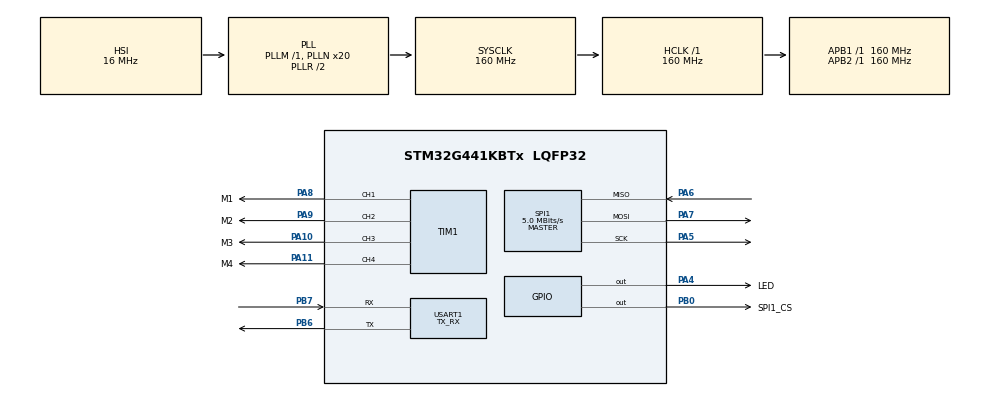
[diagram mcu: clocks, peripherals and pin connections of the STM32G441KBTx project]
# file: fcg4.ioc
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Mcu.Family=STM32G4
Mcu.Name=STM32G441KBTx
Mcu.Package=LQFP32
NVIC.PriorityGroup=NVIC_PRIORITYGROUP_4
NVIC.USART1_IRQn=true\:1\:0\:true\:false\:true\:true\:true
PA10.GPIO_Label=M3
PA10.GPIO_Speed=GPIO_SPEED_FREQ_VERY_HIGH
PA10.Signal=S_TIM1_CH3
PA11.GPIO_Label=M4
PA11.GPIO_Speed=GPIO_SPEED_FREQ_VERY_HIGH
PA11.Signal=S_TIM1_CH4
PA13.Mode=Serial_Wire
PA13.Signal=SYS_JTMS-SWDIO
PA14.Mode=Serial_Wire
PA14.Signal=SYS_JTCK-SWCLK
PA4.GPIO_Label=LED
PA4.GPIO_Speed=GPIO_SPEED_FREQ_VERY_HIGH
PA4.Signal=GPIO_Output
PA5.Mode=Full_Duplex_Master
PA5.Signal=SPI1_SCK
PA6.Mode=Full_Duplex_Master
PA6.Signal=SPI1_MISO
PA7.Mode=Full_Duplex_Master
PA7.Signal=SPI1_MOSI
PA8.GPIO_Label=M1
PA8.GPIO_Speed=GPIO_SPEED_FREQ_VERY_HIGH
PA8.Signal=S_TIM1_CH1
PA9.GPIO_Label=M2
PA9.GPIO_Speed=GPIO_SPEED_FREQ_VERY_HIGH
PA9.Signal=S_TIM1_CH2
PB0.GPIO_Label=SPI1_CS
PB0.GPIO_Speed=GPIO_SPEED_FREQ_VERY_HIGH
PB0.PinState=GPIO_PIN_SET
PB0.Signal=GPIO_Output
PB6.GPIO_Speed=GPIO_SPEED_FREQ_VERY_HIGH
PB6.Mode=Asynchronous
PB6.Signal=USART1_TX
PB7.GPIO_Speed=GPIO_SPEED_FREQ_VERY_HIGH
PB7.Mode=Asynchronous
PB7.Signal=USART1_RX
ProjectManager.HeapSize=0x200
ProjectManager.StackSize=0x400
ProjectManager.TargetToolchain=STM32CubeIDE
RCC.ADC12Freq_Value=160000000
RCC.AHBFreq_Value=160000000
RCC.APB1Freq_Value=160000000
RCC.APB1TimFreq_Value=160000000
RCC.APB2Freq_Value=160000000
RCC.APB2TimFreq_Value=160000000
RCC.CortexFreq_Value=160000000
RCC.EXTERNAL_CLOCK_VALUE=12288000
RCC.HCLKFreq_Value=160000000
RCC.HSE_VALUE=8000000
RCC.HSI48_VALUE=48000000
RCC.HSI_VALUE=16000000
RCC.LSE_VALUE=32768
RCC.PLLN=20
RCC.SYSCLKFreq_VALUE=160000000
RCC.SYSCLKSource=RCC_SYSCLKSOURCE_PLLCLK
RCC.USBFreq_Value=160000000
RCC.VCOOutputFreq_Value=320000000
SH.S_TIM1_CH1.0=TIM1_CH1,PWM Generation1 CH1
SH.S_TIM1_CH2.0=TIM1_CH2,PWM Generation2 CH2
SH.S_TIM1_CH3.0=TIM1_CH3,PWM Generation3 CH3
SH.S_TIM1_CH4.0=TIM1_CH4,PWM Generation4 CH4
SPI1.BaudRatePrescaler=SPI_BAUDRATEPRESCALER_32
SPI1.CLKPhase=SPI_PHASE_2EDGE
SPI1.CLKPolarity=SPI_POLARITY_HIGH
SPI1.CalculateBaudRate=5.0 MBits/s
SPI1.DataSize=SPI_DATASIZE_8BIT
SPI1.Direction=SPI_DIRECTION_2LINES
SPI1.Mode=SPI_MODE_MASTER
SPI1.VirtualType=VM_MASTER
TIM1.Channel-PWM\ Generation1\ CH1=TIM_CHANNEL_1
TIM1.Channel-PWM\ Generation2\ CH2=TIM_CHANNEL_2
TIM1.Channel-PWM\ Generation3\ CH3=TIM_CHANNEL_3
TIM1.Channel-PWM\ Generation4\ CH4=TIM_CHANNEL_4
TIM2.Prescaler=160-1
USART1.AutoBaudRateEnableParam=UART_ADVFEATURE_AUTOBAUDRATE_ENABLE
USART1.Mode=MODE_TX_RX
USART1.OneBitSampling=UART_ONE_BIT_SAMPLE_DISABLE
USART1.VirtualMode-Asynchronous=VM_ASYNC
VP_SYS_VS_DBSignals.Mode=DisableDeadBatterySignals
VP_TIM1_VS_ClockSourceINT.Mode=Internal
VP_TIM2_VS_ClockSourceINT.Mode=Internal
board=custom

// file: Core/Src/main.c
/* USER CODE BEGIN Header */
/**
 ******************************************************************************
 * @file           : main.c
 * @brief          : Main program body
 ******************************************************************************
 * @attention
 *
 * <h2><center>&copy; Copyright (c) 2021 STMicroelectronics.
 * All rights reserved.</center></h2>
 *
 * This software component is licensed by ST under BSD 3-Clause license,
 * the "License"; You may not use this file except in compliance with the
 * License. You may obtain a copy of the License at:
 *                        opensource.org/licenses/BSD-3-Clause
 *
 ******************************************************************************
 */
/* USER CODE END Header */
#include "main.h"
#include "spi.h"
#include "tim.h"
#include "usart.h"
#include "gpio.h"

/* USER CODE BEGIN Includes */
#include "flight_controler.h"
/* USER CODE END Includes */

void SystemClock_Config(void);

int main(void)
{

  /* MCU Configuration--------------------------------------------------------*/

  /* Reset of all peripherals, Initializes the Flash interface and the Systick. */
  HAL_Init();

  /* Configure the system clock */
  SystemClock_Config();

  /* Initialize all configured peripherals */
  MX_GPIO_Init();
  MX_SPI1_Init();
  MX_TIM1_Init();
  MX_USART1_UART_Init();
  MX_TIM2_Init();
  /* USER CODE BEGIN 2 */

	flight_controler_init();
  /* USER CODE END 2 */

  /* Infinite loop */
  /* USER CODE BEGIN WHILE */
	while (1) {
		flight_controler_run();

    /* USER CODE END WHILE */

	}
}

void SystemClock_Config(void)
{
  RCC_OscInitTypeDef RCC_OscInitStruct = {0};
  RCC_ClkInitTypeDef RCC_ClkInitStruct = {0};
  RCC_PeriphCLKInitTypeDef PeriphClkInit = {0};

  /** Configure the main internal regulator output voltage
  */
  HAL_PWREx_ControlVoltageScaling(PWR_REGULATOR_VOLTAGE_SCALE1_BOOST);
  /** Initializes the RCC Oscillators according to the specified parameters
  * in the RCC_OscInitTypeDef structure.
  */
  RCC_OscInitStruct.OscillatorType = RCC_OSCILLATORTYPE_HSI;
  RCC_OscInitStruct.HSIState = RCC_HSI_ON;
  RCC_OscInitStruct.HSICalibrationValue = RCC_HSICALIBRATION_DEFAULT;
  RCC_OscInitStruct.PLL.PLLState = RCC_PLL_ON;
  RCC_OscInitStruct.PLL.PLLSource = RCC_PLLSOURCE_HSI;
  RCC_OscInitStruct.PLL.PLLM = RCC_PLLM_DIV1;
  RCC_OscInitStruct.PLL.PLLN = 20;
  RCC_OscInitStruct.PLL.PLLP = RCC_PLLP_DIV2;
  RCC_OscInitStruct.PLL.PLLQ = RCC_PLLQ_DIV2;
  RCC_OscInitStruct.PLL.PLLR = RCC_PLLR_DIV2;
  if (HAL_RCC_OscConfig(&RCC_OscInitStruct) != HAL_OK)
  {
    Error_Handler();
  }
  /** Initializes the CPU, AHB and APB buses clocks
  */
  RCC_ClkInitStruct.ClockType = RCC_CLOCKTYPE_HCLK|RCC_CLOCKTYPE_SYSCLK
                              |RCC_CLOCKTYPE_PCLK1|RCC_CLOCKTYPE_PCLK2;
  RCC_ClkInitStruct.SYSCLKSource = RCC_SYSCLKSOURCE_PLLCLK;
  RCC_ClkInitStruct.AHBCLKDivider = RCC_SYSCLK_DIV1;
  RCC_ClkInitStruct.APB1CLKDivider = RCC_HCLK_DIV1;
  RCC_ClkInitStruct.APB2CLKDivider = RCC_HCLK_DIV1;

  if (HAL_RCC_ClockConfig(&RCC_ClkInitStruct, FLASH_LATENCY_4) != HAL_OK)
  {
    Error_Handler();
  }
  /** Initializes the peripherals clocks
  */
  PeriphClkInit.PeriphClockSelection = RCC_PERIPHCLK_USART1;
  PeriphClkInit.Usart1ClockSelection = RCC_USART1CLKSOURCE_PCLK2;
  if (HAL_RCCEx_PeriphCLKConfig(&PeriphClkInit) != HAL_OK)
  {
    Error_Handler();
  }
}

void Error_Handler(void)
{
	__disable_irq();
	while (1) {
	}
}

/************************ (C) COPYRIGHT STMicroelectronics *****END OF FILE****/
